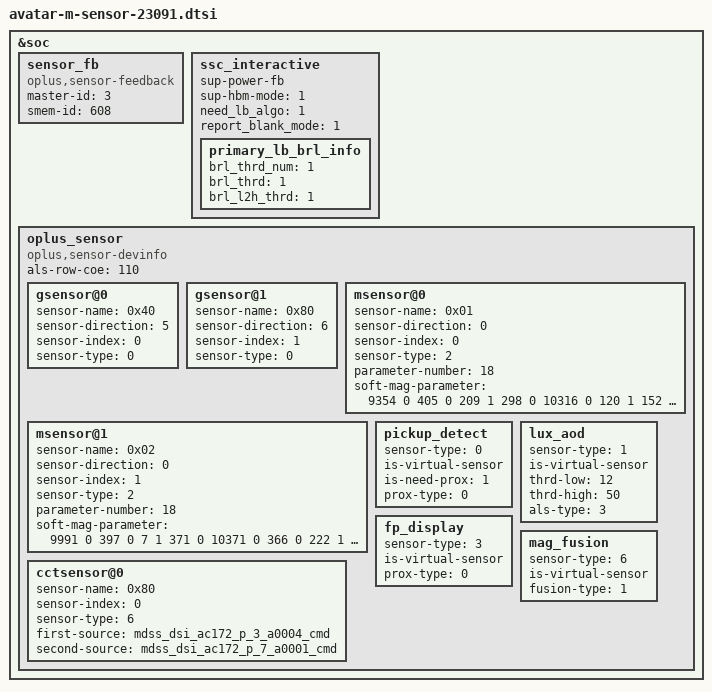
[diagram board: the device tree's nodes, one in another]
&soc {
	sensor_fb: sensor_fb {
		compatible = "oplus,sensor-feedback";
		master-id  = <3>;
		smem-id    = <608>;
	};

	ssc_interactive: ssc_interactive {
		sup-power-fb;
		sup-hbm-mode = <1>;
		need_lb_algo = <1>;
		report_blank_mode = <1>;

		primary_lb_brl_info {
			brl_thrd_num = <1>;
			brl_thrd = <1>;
			brl_l2h_thrd = <1>;
		};
        };

	oplus_sensor {
			compatible = "oplus,sensor-devinfo";
			als-row-coe = <110>;

			/* enum {
				LSM6DSM = 0x01,
				BMI160 = 0x02,
				LSM6DS3_C = 0x04,
				BMI260 = 0x08,
				LSM6DSO = 0x10,
				ICM4X6XX = 0x20,
				ICM4X607 = 0x40,
				BMI3X0 = 0x80,
				LIS2HH12 = 0x81,
				BMA420 = 0x82,
				ICM456XX = 0x84,
				SC7A20   = 0x85,
				STK83XX  = 0x86,
			}; */
			gsensor@0 {
					sensor-name = <0x40>;     // ICM4X607
					sensor-direction = <5>;
					sensor-index = <0>;       // source num
					sensor-type = <0>;        // OPLUS_ACCEL
			};
			gsensor@1 {
					sensor-name = <0x80>;     // BMI3X0
					sensor-direction = <6>;
					sensor-index = <1>;       // source num
					sensor-type = <0>;        // OPLUS_ACCEL
			};

			/* enum {AKM0991X = 0x01, MMC5603 = 0x02, MXG4300 = 0x04};*/
			msensor@0 {
					sensor-name = <0x01>;     //AKM0991X
					sensor-direction = <0>;
					sensor-index = <0>;
					sensor-type = <2>;        //OPLUS_MAG
					parameter-number= <18>;
					soft-mag-parameter = <9354 0 405 0 209 1 298 0 10316 0 120 1 152 1 28 1 10841 0>; // e00 sign e01 sign...
			};
			msensor@1 {
					sensor-name = <0x02>;    // MMC5603
					sensor-direction = <0>;
					sensor-index = <1>;
					sensor-type = <2>;       // OPLUS_MAG
					parameter-number= <18>;
					soft-mag-parameter = <9991 0 397 0 7 1 371 0 10371 0 366 0 222 1 115 1 11204 0>; // e00 sign e01 sign...
			};

			cctsensor@0 {
				sensor-name = <0x80>;            // stk36c01
				sensor-index = <0>;              // source num
				sensor-type = <6>;               // OPLUS_CCT
				first-source = "mdss_dsi_ac172_p_3_a0004_cmd";
				second-source = "mdss_dsi_ac172_p_7_a0001_cmd";
			};

			/* virtual sensor
			enum sensor_algo_id {
				OPLUS_PICKUP_DETECT,
				OPLUS_LUX_AOD,
				OPLUS_TP_GESTURE,
				OPLUS_FP_DISPLAY,
				OPLUS_FREE_FALL,
				OPLUS_CAMERA_PROTECT,
				OPLUS_MAG_FUSION,
				OPLUS_MEASUREMENT,
				SENSOR_ALGO_NUM
			}; */
			pickup_detect {
					sensor-type = <0>; // OPLUS_PICKUP_DETECT
					is-virtual-sensor;
					is-need-prox = <1>;
					prox-type = <0>; // 0 - proximity; 1 - proximity_fake
			};
			lux_aod {
				sensor-type = <1>; // OPLUS_LUX_AOD
				is-virtual-sensor;
				thrd-low = <12>;
				thrd-high = <50>;
				als-type = <3>;   // type WISE_RGB
			};
			fp_display {
				sensor-type = <3>;  // OPLUS_FP_DISPLAY
				is-virtual-sensor;
				prox-type = <0>; // 0 - proximity; 1 - proximity_fake
			};
			mag_fusion {
				sensor-type = <6>;  // OPLUS_MAG_FUSION
				is-virtual-sensor;
				fusion-type = <1>;
			};
	};
};

